# R7FA6M5BH register map
Vendor: Renesas Electronics Corporation; Series: RA6; File version: 1.20.01
CPU: CM33 r0p4, little endian, MPU, FPU, VTOR, 4 interrupt priority bits, 96 interrupts
Registers are 32-bit, read-write, reset 0x0 unless marked. A register's access mark holds for its fields unless they carry their own. Offsets are from the block's base; [hi:lo] are bit positions; {n}, {i} and the like mark numbered series.

## IIC0 — Inter-Integrated Circuit 0
Base 0x4009F000
Same registers: IIC1 0x4009F100, IIC2 0x4009F200
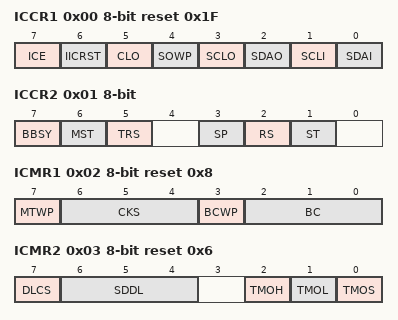
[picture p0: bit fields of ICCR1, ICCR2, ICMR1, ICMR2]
0x00 ICCR1 8-bit reset 0x1F — I2C Bus Control Register 1
  [7] ICE — I2C Bus Interface Enable
    0=Disable (SCLn and SDAn pins in inactive state); 1=Enable (SCLn and SDAn pins in active state)
  [6] IICRST — I2C Bus Interface Internal Reset
    0=Release IIC reset or internal reset; 1=Initiate IIC reset or internal reset
  [5] CLO — Extra SCL Clock Cycle Output
    0=Do not output extra SCL clock cycle (default); 1=Output extra SCL clock cycle
  [4] SOWP wo — SCLO/SDAO Write Protect
    0=Write enable SCLO and SDAO bits; 1=Write protect SCLO and SDAO bits
  [3] SCLO — SCL Output Control/Monitor
    0=Read: IIC drives SCLn pin low Write: IIC drives SCLn pin low; 1=Read: IIC releases SCLn pin Write: IIC releases SCLn pin
  [2] SDAO — SDA Output Control/Monitor
    0=Read: IIC drives SDAn pin low Write: IIC drives SDAn pin low; 1=Read: IIC releases SDAn pin Write: IIC releases SDAn pin
  [1] SCLI ro — SCL Line Monitor
    0=SCLn line is low; 1=SCLn line is high
  [0] SDAI ro — SDA Line Monitor
    0=SDAn line is low; 1=SDAn line is high
0x01 ICCR2 8-bit — I2C Bus Control Register 2
  [7] BBSY ro — Bus Busy Detection Flag
    0=I2C bus released (bus free state); 1=I2C bus occupied (bus busy state)
  [6] MST — Master/Slave Mode
    0=Slave mode; 1=Master mode
  [5] TRS — Transmit/Receive Mode
    0=Receive mode; 1=Transmit mode
  [3] SP — Stop Condition Issuance Request
    0=Do not issue a stop condition request; 1=Issue a stop condition request
  [2] RS — Restart Condition Issuance Request
    0=Do not issue a restart condition request; 1=Issue a restart condition request
  [1] ST — Start Condition Issuance Request
    0=Do not issue a start condition request; 1=Issue a start condition request
0x02 ICMR1 8-bit reset 0x8 — I2C Bus Mode Register 1
  [7] MTWP — MST/TRS Write Protect
    0=Write protect MST and TRS bits in ICCR2; 1=Write enable MST and TRS bits in ICCR2
  [6:4] CKS — Internal Reference Clock Select
  [3] BCWP wo — BC Write Protect
    0=Write enable BC[2:0] bits; 1=Write protect BC[2:0] bits
  [2:0] BC — Bit Counter
    0=9 bits; {v}={v+1} bits (v=1..7)
0x03 ICMR2 8-bit reset 0x6 — I2C Bus Mode Register 2
  [7] DLCS — SDA Output Delay Clock Source Select
    0=Select internal reference clock (IIC-phi) as the clock source for SDA output delay counter; 1=Select internal reference clock divided by 2 (IIC-phi/2) as the clock source for SDA output delay counter
  [6:4] SDDL — SDA Output Delay Counter
    0=No output delay; 1=1 IIC-phi cycle (When ICMR2.DLCS = 0 (IIC-phi)) 1 or 2 IIC-phi cycles (When ICMR2.DLCS = 1 (IIC-phi/2)); 2=2 IIC-phi cycles (When ICMR2.DLCS = 0 (IIC-phi)) 3 or 4 IIC-phi cycles (When ICMR2.DLCS = 1 (IIC-phi/2)); 3=3 IIC-phi cycles (When ICMR2.DLCS = 0 (IIC-phi)) 5 or 6 IIC-phi cycles (When ICMR2.DLCS = 1 (IIC-phi/2)); 4=4 IIC-phi cycles (When ICMR2.DLCS = 0 (IIC-phi)) 7 or 8 IIC-phi cycles (When ICMR2.DLCS = 1 (IIC-phi/2)); 5=5 IIC-phi cycles (When ICMR2.DLCS = 0 (IIC-phi)) 9 or 10 IIC-phi cycles (When ICMR2.DLCS = 1 (IIC-phi/2)); 6=6 IIC-phi cycles (When ICMR2.DLCS = 0 (IIC-phi)) 11 or 12 IIC-phi cycles (When ICMR2.DLCS = 1 (IIC-phi/2)); 7=7 IIC-phi cycles (When ICMR2.DLCS = 0 (IIC-phi)) 13 or 14 IIC-phi cycles (When ICMR2.DLCS = 1 (IIC-phi/2))
  [2] TMOH — Timeout H Count Control
    0=Disable count while SCLn line is high; 1=Enable count while SCLn line is high
  [1] TMOL — Timeout L Count Control
    0=Disable count while SCLn line is low; 1=Enable count while SCLn line is low
  [0] TMOS — Timeout Detection Time Select
    0=Select long mode; 1=Select short mode
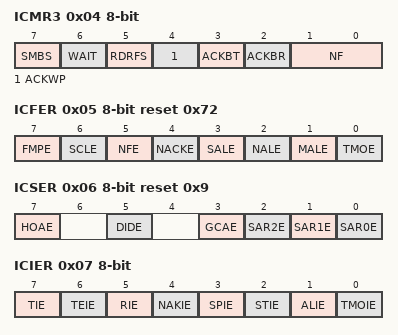
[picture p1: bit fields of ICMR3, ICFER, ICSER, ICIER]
0x04 ICMR3 8-bit — I2C Bus Mode Register 3
  [7] SMBS — SMBus/I2C Bus Select
    0=Select I2C Bus; 1=Select SMBus
  [6] WAIT — Low-hold is released by reading ICDRR.
    0=No wait (The SCLn line is not held low during the period between the 9th clock cycle and the 1st clock cycle.); 1=Wait (The SCLn line is held low during the period between the 9th clock cycle and the 1st clock cycle.)
  [5] RDRFS — RDRF Flag Set Timing Select
    0=Set the RDRF flag on the rising edge of the 9th SCL clock cycle. The SCLn line is not held low on the falling edge of the 8th clock cycle.; 1=Set the RDRF flag on the rising edge of the 8th SCL clock cycle. The SCLn line is held low on the falling edge of the 8th clock cycle.
  [4] ACKWP — ACKBT Write Protect
    0=Write protect ACKBT bit; 1=Write enable ACKBT bit
  [3] ACKBT — Transmit Acknowledge
    0=Send 0 as the acknowledge bit (ACK transmission); 1=Send 1 as the acknowledge bit (NACK transmission)
  [2] ACKBR ro — Receive Acknowledge
    0=0 received as the acknowledge bit (ACK reception); 1=1 received as the acknowledge bit (NACK reception)
  [1:0] NF — Noise Filter Stage Select
    0=Filter out noise of up to 1 IIC-phi cycle (single-stage filter); 1=Filter out noise of up to 2 IIC-phi cycles (2-stage filter); 2=Filter out noise of up to 3 IIC-phi cycles (3-stage filter); 3=Filter out noise of up to 4 IIC-phi cycles (4-stage filter)
0x05 ICFER 8-bit reset 0x72 — I2C Bus Function Enable Register
  [7] FMPE — Fast-Mode Plus Enable
    0=Do not use the Fm+ slope control circuit for the SCLn and SDAn pins; 1=Use the Fm+ slope control circuit for the SCLn and SDAn pins
  [6] SCLE — SCL Synchronous Circuit Enable
    0=Do not use the SCL synchronous circuit; 1=Use the SCL synchronous circuit
  [5] NFE — Digital Noise Filter Circuit Enable
    0=Do not use the digital noise filter circuit; 1=Use the digital noise filter circuit
  [4] NACKE — NACK Reception Transfer Suspension Enable
    0=Do not suspend transfer operation during NACK reception (disable transfer suspension); 1=Suspend transfer operation during NACK reception (enable transfer suspension)
  [3] SALE — Slave Arbitration-Lost Detection Enable
    0=Disable; 1=Enable
  [2] NALE — NACK Transmission Arbitration-Lost Detection Enable
    0=Disable; 1=Enable
  [1] MALE — Master Arbitration-Lost Detection Enable
    0=Disable the arbitration-lost detection function and disable automatic clearing of the MST and TRS bits in ICCR2 when arbitration is lost; 1=Enable the arbitration-lost detection function and enable automatic clearing of the MST and TRS bits in ICCR2 when arbitration is lost
  [0] TMOE — Timeout Function Enable
    0=Disable; 1=Enable
0x06 ICSER 8-bit reset 0x9 — I2C Bus Status Enable Register
  [7] HOAE — Host Address Enable
    0=Disable host address detection; 1=Enable host address detection
  [5] DIDE — Device-ID Address Detection Enable
    0=Disable device-ID address detection; 1=Enable device-ID address detection
  [3] GCAE — General Call Address Enable
    0=Disable general call address detection; 1=Enable general call address detection
  [2] SAR2E — Slave Address Register 2 Enable
    0=Disable slave address in SARL2 and SARU2; 1=Enable slave address in SARL2 and SARU2
  [1] SAR1E — Slave Address Register 1 Enable
    0=Disable slave address in SARL1 and SARU1; 1=Enable slave address in SARL1 and SARU1
  [0] SAR0E — Slave Address Register 0 Enable
    0=Disable slave address in SARL0 and SARU0; 1=Enable slave address in SARL0 and SARU0
0x07 ICIER 8-bit — I2C Bus Interrupt Enable Register
  [7] TIE — Transmit Data Empty Interrupt Request Enable
    0=Disable transmit data empty interrupt (IICn_TXI) request; 1=Enable transmit data empty interrupt (IICn_TXI) request
  [6] TEIE — Transmit End Interrupt Request Enable
    0=Disable transmit end interrupt (IICn_TEI) request; 1=Enable transmit end interrupt (IICn_TEI) request
  [5] RIE — Receive Data Full Interrupt Request Enable
    0=Disable receive data full interrupt (IICn_RXI) request; 1=Enable receive data full interrupt (IICn_RXI) request
  [4] NAKIE — NACK Reception Interrupt Request Enable
    0=Disable NACK reception interrupt (NAKI) request; 1=Enable NACK reception interrupt (NAKI) request
  [3] SPIE — Stop Condition Detection Interrupt Request Enable
    0=Disable stop condition detection interrupt (SPI) request; 1=Enable stop condition detection interrupt (SPI) request
  [2] STIE — Start Condition Detection Interrupt Request Enable
    0=Disable start condition detection interrupt (STI) request; 1=Enable start condition detection interrupt (STI) request
  [1] ALIE — Arbitration-Lost Interrupt Request Enable
    0=Disable arbitration-lost interrupt (ALI) request; 1=Enable arbitration-lost interrupt (ALI) request
  [0] TMOIE — Timeout Interrupt Request Enable
    0=Disable timeout interrupt (TMOI) request; 1=Enable timeout interrupt (TMOI) request
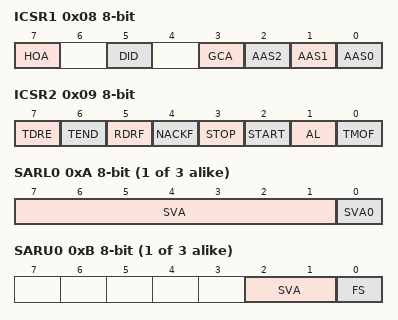
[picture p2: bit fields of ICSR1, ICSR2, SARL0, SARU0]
0x08 ICSR1 8-bit — I2C Bus Status Register 1
  [7] HOA — Host Address Detection Flag
    0=Host address not detected; 1=Host address detected
  [5] DID — Device-ID Address Detection Flag
    0=Device-ID command not detected; 1=Device-ID command detected
  [3] GCA — General Call Address Detection Flag
    0=General call address not detected; 1=General call address detected
  [2] AAS2 — Slave Address 2 Detection Flag
    0=Slave address 2 not detected; 1=Slave address 2 detected
  [1] AAS1 — Slave Address 1 Detection Flag
    0=Slave address 1 not detected; 1=Slave address 1 detected
  [0] AAS0 — Slave Address 0 Detection Flag
    0=Slave address 0 not detected; 1=Slave address 0 detected
0x09 ICSR2 8-bit — I2C Bus Status Register 2
  [7] TDRE ro — Transmit Data Empty Flag
    0=ICDRT contains transmit data; 1=ICDRT contains no transmit data
  [6] TEND — Transmit End Flag
    0=Data being transmitted; 1=Data transmit complete
  [5] RDRF — Receive Data Full Flag
    0=ICDRR contains no receive data; 1=ICDRR contains receive data
  [4] NACKF — NACK Detection Flag
    0=NACK not detected; 1=NACK detected
  [3] STOP — Stop Condition Detection Flag
    0=Stop condition not detected; 1=Stop condition detected
  [2] START — Start Condition Detection Flag
    0=Start condition not detected; 1=Start condition detected
  [1] AL — Arbitration-Lost Flag
    0=Arbitration not lost; 1=Arbitration lost
  [0] TMOF — Timeout Detection Flag
    0=Timeout not detected; 1=Timeout detected
{0xA+2i} SARL{i} (i=0..2) 8-bit — Slave Address Register Ly
  [7:1] SVA — 7-bit Address/10-bit Address Lower Bits
  [0] SVA0 — 10-bit Address LSB
{0xB+2i} SARU{i} (i=0..2) 8-bit — Slave Address Register Uy
  [2:1] SVA — 10-bit Address Upper Bits
  [0] FS — 7-bit/10-bit Address Format Select
    0=Select 7-bit address format; 1=Select 10-bit address format
0x10 ICBRL 8-bit reset 0xFF — I2C Bus Bit Rate Low-Level Register
  [4:0] BRL — Bit Rate Low-Level Period
0x11 ICBRH 8-bit reset 0xFF — I2C Bus Bit Rate High-Level Register
  [4:0] BRH — Bit Rate High-Level Period
0x12 ICDRT 8-bit reset 0xFF — I2C Bus Transmit Data Register
0x13 ICDRR 8-bit ro — I2C Bus Receive Data Register
